# mcr_me17 register map
Registers are access not given, no defined reset value unless marked. A register's access mark holds for its fields unless they carry their own. Offsets are from the block's base; lines under a group give offsets from that group; [hi:lo] are bit positions; {n}, {i} and the like mark numbered series; 'fields as' and 'values as' point back to an identical list; <NAME> marks a mode.

## Memory map
0x40006C00 MCR size 0x400 — Misc Control.

## MCR — Misc Control.
Base 0x40006C00
0x00 ECCEN — ECC Enable Register
  [0] RAM0 — ECC System RAM0 Enable.
    0=dis (disabled.); 1=en (enabled.)
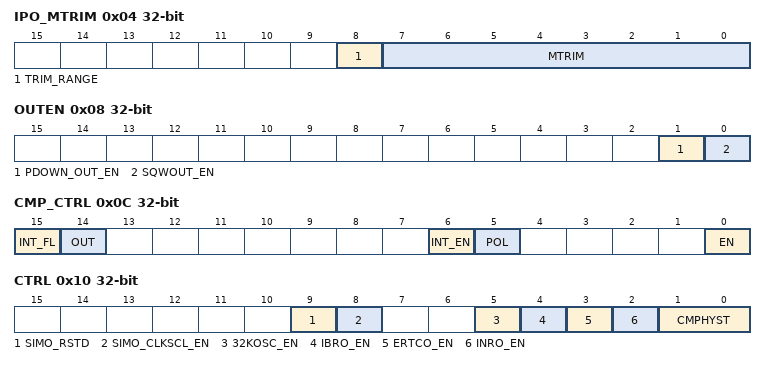
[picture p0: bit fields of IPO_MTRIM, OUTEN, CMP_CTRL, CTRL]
0x04 IPO_MTRIM — IPO Manual Register
  [8] TRIM_RANGE — Trim Range Select.
  [7:0] MTRIM — Manual Trim Value.
0x08 OUTEN — Output Enable Register
  [1] PDOWN_OUT_EN — Power Down Output Enable.
  [0] SQWOUT_EN — Square Wave Output Enable.
0x0C CMP_CTRL — Comparator Control Register.
  [15] INT_FL — IRQ Flag
  [14] OUT — Comparator Output State.
  [6] INT_EN — IRQ Enable.
  [5] POL — Polarity Select
  [0] EN — Comparator Enable.
0x10 CTRL — Miscellaneous Control Register.
  [9] SIMO_RSTD — SIMO System Reset Disable.
  [8] SIMO_CLKSCL_EN — SIMO Clock Scaling Enable.
  [5] 32KOSC_EN — Enable 32K Oscillator input.
  [4] IBRO_EN — IBRO Enable.
  [3] ERTCO_EN — ERTCO Enable.
  [2] INRO_EN — INRO Enable.
  [1:0] CMPHYST — Comparator hysteresis control.
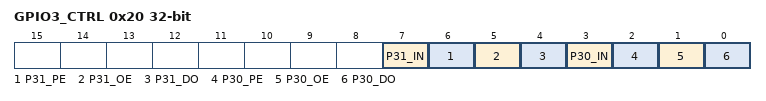
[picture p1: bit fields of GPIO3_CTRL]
0x20 GPIO3_CTRL — GPIO3 Pin Control Register.
  [7] P31_IN — GPIO3 Pin 1 Input Status.
  [6] P31_PE — GPIO3 Pin 1 Pull-up Enable.
  [5] P31_OE — GPIO3 Pin 1 Output Enable.
  [4] P31_DO — GPIO3 Pin 1 Data Output.
  [3] P30_IN — GPIO3 Pin 0 Input Status.
  [2] P30_PE — GPIO3 Pin 0 Pull-up Enable.
  [1] P30_OE — GPIO3 Pin 0 Output Enable.
  [0] P30_DO — GPIO3 Pin 0 Data Output.
